# APP_PRCM register map
Vendor: Texas Instruments
Peripheral module from a debugger description file (folder xwrl64xx).
Registers are 32-bit, access per field, no defined reset value unless marked. A register's access mark holds for its fields unless they carry their own. Offsets are as the file gives them; lines under a group give offsets from that group; [hi:lo] are bit positions; {n}, {i} and the like mark numbered series; 'fields as' and 'values as' point back to an identical list; <NAME> marks a mode.

## APP_PRCM
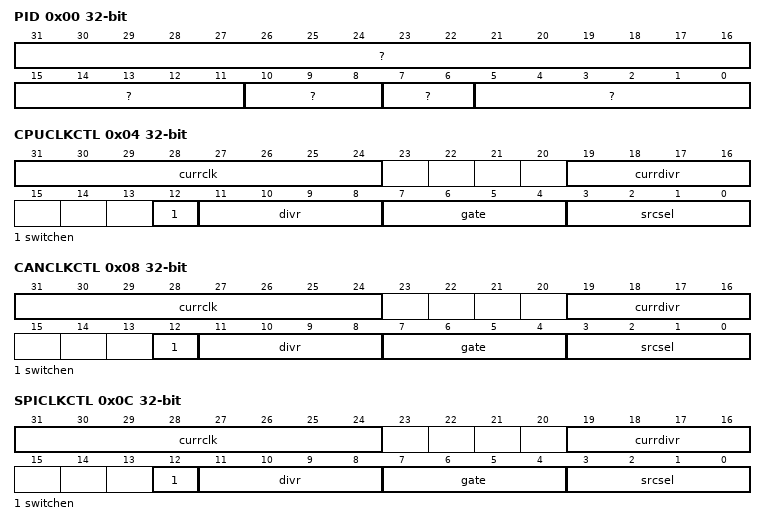
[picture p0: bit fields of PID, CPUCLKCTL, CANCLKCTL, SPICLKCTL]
0x00 PID ro
  [31:16] ?, [15:11] ?, [10:8] ?, [7:6] ?, [5:0] ?
0x04 CPUCLKCTL
  [31:24] currclk ro — Current Clock selected by GCM Clock Mux#br#0x1 : XTALCLK#br#0x2 : XTALCLKX2#br#0x4 : MDLL#br#0x8 : APLL/DPLL#br#0x10 : RCCLK
  [19:16] currdivr ro — Gives the current divr setting used by the clock divider.
  [12] switchen rw — 1'b1 : Switch to the new divide ratio set by divr bits above. This happens when output clock of the divider is transitioning from 0->1,
  [11:8] divr rw — Divide value#br#0x0 : div1#br#0x1 : div2#br#0x2 : div3#br#.#br#.#br#0xF = div16
  [7:4] gate rw — 0x0 : Enable the Clock#br#0x7 : Gate the clock
  [3:0] srcsel rw — Slect the source clock:#br#0x0 : XTALCLK#br#0x1 : XTALCLKX2#br#0x2 : MDLL#br#0x3 : APLL/DPLL#br#0x4 : RCCLK#br#For other values if the lower 3 bits matches with above, corresponding clock is selected.
0x08 CANCLKCTL
  [31:24] currclk ro — Current Clock selected by GCM Clock Mux#br#0x1 : XTALCLK#br#0x2 : XTALCLKX2#br#0x4 : MDLL#br#0x8 : APLL/DPLL#br#0x10 : RCCLK
  [19:16] currdivr ro — Gives the current divr setting used by the clock divider.
  [12] switchen rw — 1'b1 : Switch to the new divide ratio set by divr bits above. This happens when output clock of the divider is transitioning from 0->1,
  [11:8] divr rw — Divide value#br#0x0 : div1#br#0x1 : div2#br#0x2 : div3#br#.#br#.#br#0xF = div16
  [7:4] gate rw — 0x0 : Enable the Clock#br#0x7 : Gate the clock
  [3:0] srcsel rw — 0x0 : XTALCLK#br#0x1 : XTALCLKX2#br#0x2 : MDLL#br#0x3 : APLL/DPLL#br#0x4 : RCCLK#br#For other values if the lower 3 bits matches with above, corresponding clock is selected.
0x0C SPICLKCTL
  fields as CANCLKCTL
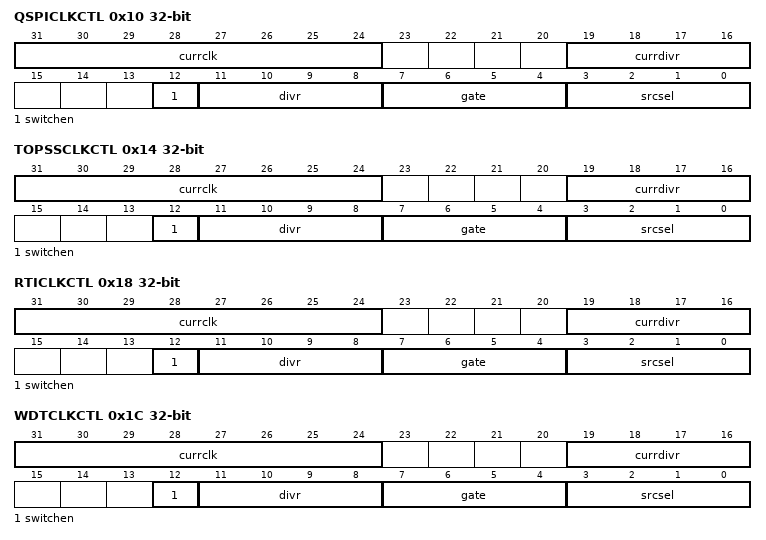
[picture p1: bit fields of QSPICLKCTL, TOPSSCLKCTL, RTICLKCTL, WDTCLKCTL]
0x10 QSPICLKCTL
  fields as CANCLKCTL
0x14 TOPSSCLKCTL
  fields as CANCLKCTL
0x18 RTICLKCTL
  [31:24] currclk ro — Current Clock selected by GCM Clock Mux#br#0x1 : XTALCLK#br#0x2 : XTALCLKX2#br#0x4 : MDLL#br#0x8 : APLL/DPLL#br#0x10 : RCCLK
  [19:16] currdivr ro — Gives the current divr setting used by the clock divider.
  [12] switchen rw — 1'b1 : Switch to the new divide ratio set by divr bits above. This happens when output clock of the divider is transitioning from 0->1,
  [11:8] divr rw — Divide value#br#0x0 : div1#br#0x1 : div2#br#0x2 : div3#br#.#br#.#br#0xF = div16
  [7:4] gate rw — 0x0 : Enable the Clock#br#0x7 : Gate the clock
  [3:0] srcsel rw — 0x0 : XTALCLK#br#0x1 : REFCLK#br#For other values if the lower 3 bits matches with above, corresponding clock is selected.
0x1C WDTCLKCTL
  fields as CANCLKCTL
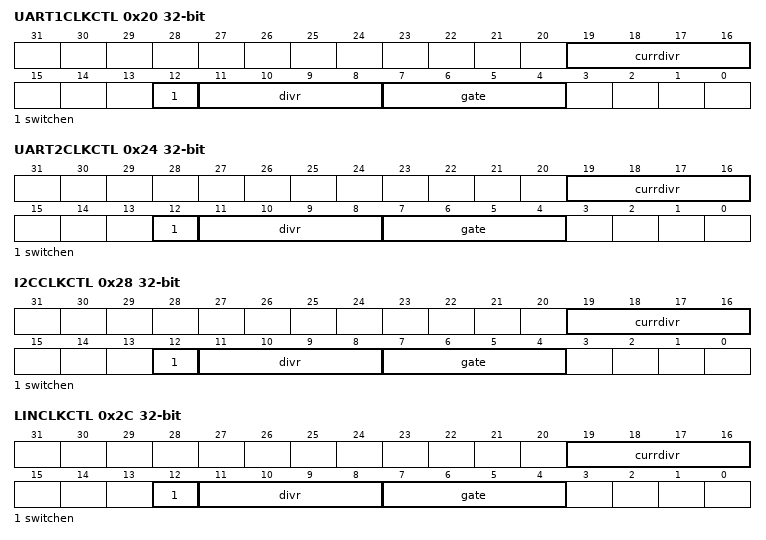
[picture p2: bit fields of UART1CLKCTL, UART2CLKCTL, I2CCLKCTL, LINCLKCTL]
0x20 UART1CLKCTL
  [19:16] currdivr ro — Gives the current divr setting used by the clock divider.
  [12] switchen rw — 1'b1 : Switch to the new divide ratio set by divr bits above. This happens when output clock of the divider is transitioning from 0->1,
  [11:8] divr rw — Divide value#br#0x0 : div1#br#0x1 : div2#br#0x2 : div3#br#.#br#.#br#0xF = div16
  [7:4] gate rw — 0x0 : Enable the Clock#br#0x7 : Gate the clock
0x24 UART2CLKCTL
  fields as UART1CLKCTL
0x28 I2CCLKCTL
  fields as UART1CLKCTL
0x2C LINCLKCTL
  fields as UART1CLKCTL
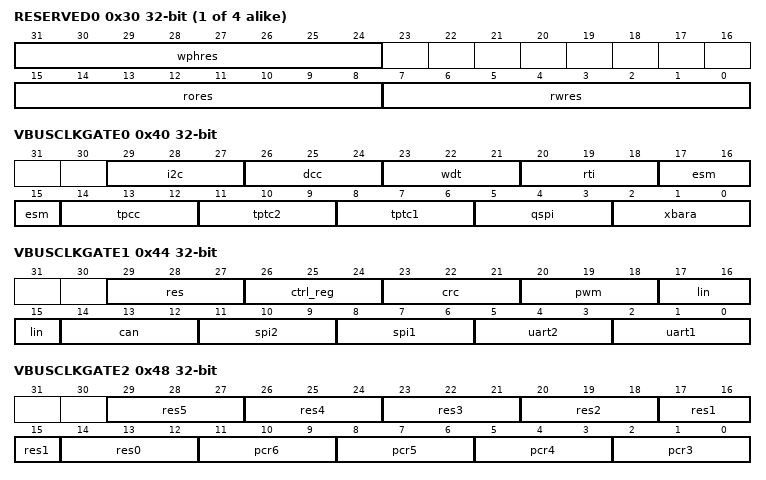
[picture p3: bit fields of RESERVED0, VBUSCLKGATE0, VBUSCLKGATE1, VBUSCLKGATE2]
{0x30+4i} RESERVED{i} (i=0..3)
  [31:24] wphres rw, [15:8] rores ro, [7:0] rwres rw
0x40 VBUSCLKGATE0 rw
  [29:27] i2c — 0x0 : Enable the Clock#br#0x7 : Gate the clock
  [26:24] dcc — 0x0 : Enable the Clock#br#0x7 : Gate the clock
  [23:21] wdt — 0x0 : Enable the Clock#br#0x7 : Gate the clock
  [20:18] rti — 0x0 : Enable the Clock#br#0x7 : Gate the clock
  [17:15] esm — 0x0 : Enable the Clock#br#0x7 : Gate the clock
  [14:12] tpcc — 0x0 : Enable the Clock#br#0x7 : Gate the clock
  [11:9] tptc2 — 0x0 : Enable the Clock#br#0x7 : Gate the clock
  [8:6] tptc1 — 0x0 : Enable the Clock#br#0x7 : Gate the clock
  [5:3] qspi — 0x0 : Enable the Clock#br#0x7 : Gate the clock
  [2:0] xbara — 0x0 : Enable the Clock#br#0x7 : Gate the clock
0x44 VBUSCLKGATE1 rw
  [29:27] res — 0x0 : Enable the Clock#br#0x7 : Gate the clock
  [26:24] ctrl_reg — 0x0 : Enable the Clock#br#0x7 : Gate the clock
  [23:21] crc — 0x0 : Enable the Clock#br#0x7 : Gate the clock
  [20:18] pwm — 0x0 : Enable the Clock#br#0x7 : Gate the clock
  [17:15] lin — 0x0 : Enable the Clock#br#0x7 : Gate the clock
  [14:12] can — 0x0 : Enable the Clock#br#0x7 : Gate the clock
  [11:9] spi2 — 0x0 : Enable the Clock#br#0x7 : Gate the clock
  [8:6] spi1 — 0x0 : Enable the Clock#br#0x7 : Gate the clock
  [5:3] uart2 — 0x0 : Enable the Clock#br#0x7 : Gate the clock
  [2:0] uart1 — 0x0 : Enable the Clock#br#0x7 : Gate the clock
0x48 VBUSCLKGATE2 rw
  [3n+14:3n+12] res{n} (n=0..5) — 0x0 : Enable the Clock#br#0x7 : Gate the clock
  [3n-7:3n-9] pcr{n} (n=3..6) — 0x0 : Enable the Clock#br#0x7 : Gate the clock
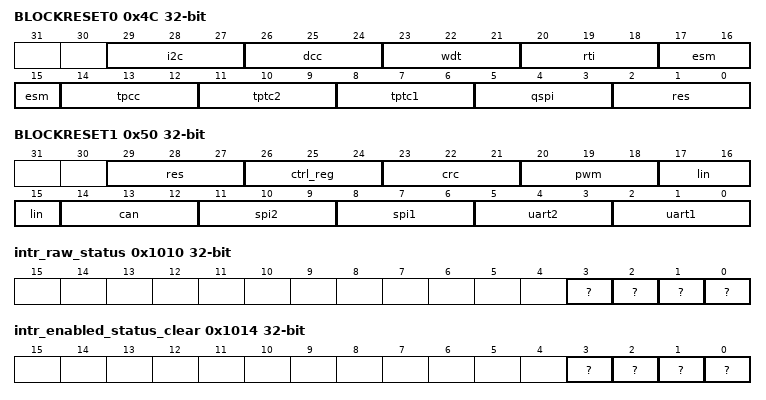
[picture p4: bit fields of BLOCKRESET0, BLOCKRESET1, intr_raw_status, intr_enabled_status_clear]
0x4C BLOCKRESET0 rw
  [29:27] i2c — 0x0 : Release the reset#br#0x7 : Assert the reset
  [26:24] dcc — 0x0 : Release the reset#br#0x7 : Assert the reset
  [23:21] wdt — 0x0 : Release the reset#br#0x7 : Assert the reset
  [20:18] rti — 0x0 : Release the reset#br#0x7 : Assert the reset
  [17:15] esm — 0x0 : Release the reset#br#0x7 : Assert the reset
  [14:12] tpcc — 0x0 : Release the reset#br#0x7 : Assert the reset
  [11:9] tptc2 — 0x0 : Release the reset#br#0x7 : Assert the reset
  [8:6] tptc1 — 0x0 : Release the reset#br#0x7 : Assert the reset
  [5:3] qspi — 0x0 : Release the reset#br#0x7 : Assert the reset
  [2:0] res — 0x0 : Release the reset#br#0x7 : Assert the reset
0x50 BLOCKRESET1 rw
  [29:27] res — 0x0 : Release the reset#br#0x7 : Assert the reset
  [26:24] ctrl_reg — 0x0 : Release the reset#br#0x7 : Assert the reset
  [23:21] crc — 0x0 : Release the reset#br#0x7 : Assert the reset
  [20:18] pwm — 0x0 : Release the reset#br#0x7 : Assert the reset
  [17:15] lin — 0x0 : Release the reset#br#0x7 : Assert the reset
  [14:12] can — 0x0 : Release the reset#br#0x7 : Assert the reset
  [11:9] spi2 — 0x0 : Release the reset#br#0x7 : Assert the reset
  [8:6] spi1 — 0x0 : Release the reset#br#0x7 : Assert the reset
  [5:3] uart2 — 0x0 : Release the reset#br#0x7 : Assert the reset
  [2:0] uart1 — 0x0 : Release the reset#br#0x7 : Assert the reset
0x1008 LOCK0_KICK0 rw — - KICK0 component
  [31:0] ?
0x100C LOCK0_KICK1 rw — - KICK1 component
  [31:0] ?
0x1010 intr_raw_status rw — Interrupt Raw Status/Set Register
  [3] ? — Proxy0 access violation error. Raw status is read. Write a 1 to set the status. Writing a 0 has no effect.
  [2] ? — Kick access violation error. Raw status is read. Write a 1 to set the status. Writing a 0 has no effect.
  [1] ? — Addressing violation error. Raw status is read. Write a 1 to set the status. Writing a 0 has no effect.
  [0] ? — Protection violation error. Raw status is read. Write a 1 to set the status. Writing a 0 has no effect.
0x1014 intr_enabled_status_clear rw — Interrupt Enabled Status/Clear register
  [3] ? — Proxy0 access violation error. Enabled status is read. Write a 1 to clear the status. Writing a 0 has no effect.
  [2] ? — Kick access violation error. Enabled status is read. Write a 1 to clear the status. Writing a 0 has no effect.
  [1] ? — Addressing violation error. Enabled status is read. Write a 1 to clear the status. Writing a 0 has no effect.
  [0] ? — Protection violation error. Enabled status is read. Write a 1 to clear the status. Writing a 0 has no effect.
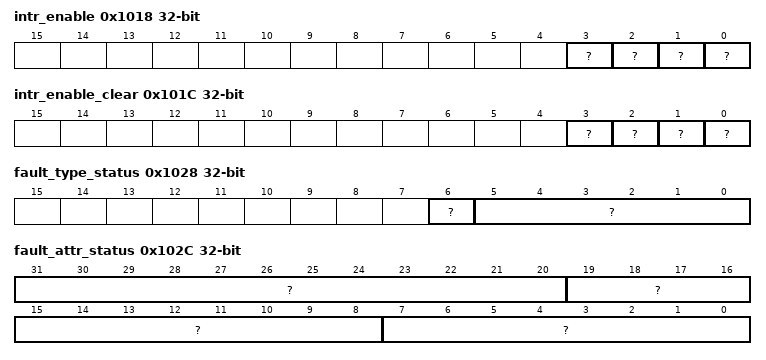
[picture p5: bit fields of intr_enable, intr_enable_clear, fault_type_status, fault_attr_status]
0x1018 intr_enable rw — Interrupt Enable register
  [3] ? — Proxy0 access violation error enable. Write a 1 to set the enable. Writing a 0 has no effect.
  [2] ? — Kick access violation error enable. Write a 1 to set the enable. Writing a 0 has no effect.
  [1] ? — Addressing violation error enable. Write a 1 to set the enable. Writing a 0 has no effect.
  [0] ? — Protection violation error enable. Write a 1 to set the enable. Writing a 0 has no effect.
0x101C intr_enable_clear rw — Interrupt Enable Clear register
  [3] ? — Proxy0 access violation error enable clear. Write a 1 to clear the enable. Writing a 0 has no effect.
  [2] ? — Kick access violation error enable clear. Write a 1 to clear the enable. Writing a 0 has no effect.
  [1] ? — Addressing violation error enable clear. Write a 1 to clear the enable. Writing a 0 has no effect.
  [0] ? — Protection violation error enable clear. Write a 1 to clear the enable. Writing a 0 has no effect.
0x1020 eoi rw
  [7:0] ? — EOI vector value. Write this with interrupt distribution value in the chip.
0x1024 fault_address ro
  [31:0] ? — Fault Address.
0x1028 fault_type_status ro
  [6] ? — Non-secure access.
  [5:0] ? — Fault Type #br# 10_0000 = Supervisor read fault - priv = 1 dir = 1 dtype != 1 #br# 01_0000 = Supervisor write fault - priv = 1 dir = 0 #br# 00_1000 = Supervisor execute fault - priv = 1 dir = 1 dtype = 1 #br# 00_0100 = User read fault - priv = 0 dir = 1 dtype = 1 #br# 00_0010 = User write fault - priv = 0 dir = 0 #br# 00_0001 = User execute fault - priv = 0 dir = 1 dtype = 1 #br# 00_0000 = No fault
0x102C fault_attr_status ro — Fault Attribute Status register
  [31:20] ? — XID.
  [19:8] ? — Route ID.
  [7:0] ? — Privilege ID.
0x1030 fault_clear wo
  [0] ? — Fault clear. Writing a 1 clears the current fault. Writing a 0 has no effect.
